AUTOSAR XML (schema 4-3-0)
package /ComponentTypes
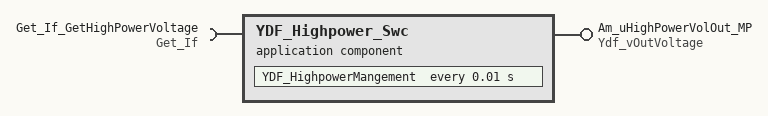
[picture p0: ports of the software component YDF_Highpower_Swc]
  application sw component type YDF_Highpower_Swc
    provide port Am_uHighPowerVolOut_MP: nonqueued-sender-com-spec{data-element=OutVoltage, init-value=0}, provided-interface=Ydf_vOutVoltage
    require port Get_If_GetHighPowerVoltage: required-interface=Get_If
      required-com-specs:
        Get_Ad_Result
        Get_io_inResult
        Get_BTS_OutResult
        Get_CAN_ActiveInf
        Icu_17_GtmCcu6_PWMIN_CH{1..4}
        Icu_17_GtmCcu6_PWMIN_PWMSCB1
        Icu_17_GtmCcu6_PWMIN_PWMSCB2
        Icu_17_GtmCcu6_PWMIN_LAMPSCB1
        Icu_17_GtmCcu6_PWMIN_LAMPSCB2
        Get_Bottom_Ver
        Get_SentData
        Get_Level_OutResult
        Get_PwmOrLevel_OutResult
        Get_Motor_OutResult
    behavior YDF_Highpower_Swc_InternalBehavior
      timing event TMT_YDF_HighpowerMangement: start-on-event=YDF_HighpowerMangement, period=0.01
      runnable YDF_HighpowerMangement
        data-send-points:
          access SEND_Am_uHighPowerVolOut_MP_OutVoltage: accessed-variable=Am_uHighPowerVolOut_MP.OutVoltage
        sync call SC_Get_If_GetHighPowerVoltage_Get_Ad_Result: operation=Get_If_GetHighPowerVoltage.Get_Ad_Result
  swc implementation YDF_Highpower_Swc_Implementation: behavior=YDF_Highpower_Swc_InternalBehavior
